# STM32G0B0VET6 register map
File version: 1.0
Registers are 32-bit, access not given, reset 0x0 unless marked. A register's access mark holds for its fields unless they carry their own. Offsets are from the block's base; [hi:lo] are bit positions; {n}, {i} and the like mark numbered series.

## USB_DRD_FS
Base 0x40005C00
{0x0+4i} CHEP{i}R (i=0..7)
0x40 CNTR
0x44 ISTR
0x48 FNR
0x4C DADDR
0x54 LPMCSR
0x58 BCDR

## PWR
Base 0x40007000
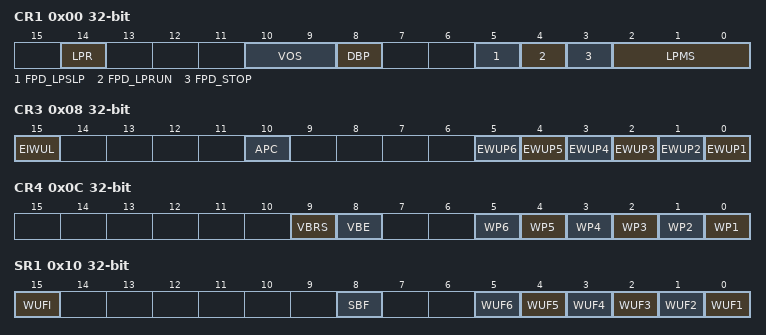
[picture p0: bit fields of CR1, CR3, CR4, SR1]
0x00 CR1
  [14] LPR, [10:9] VOS, [8] DBP, [5] FPD_LPSLP, [4] FPD_LPRUN, [3] FPD_STOP, [2:0] LPMS
0x08 CR3
  [15] EIWUL, [10] APC, [n-1] EWUP{n} (n=1..6)
0x0C CR4
  [9] VBRS, [8] VBE, [n-1] WP{n} (n=1..6)
0x10 SR1
  [15] WUFI, [8] SBF, [n-1] WUF{n} (n=1..6)
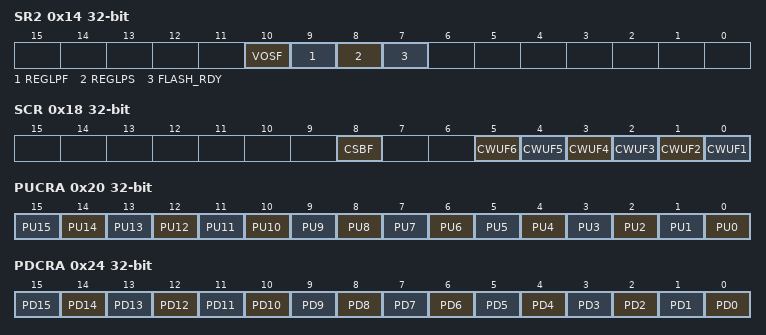
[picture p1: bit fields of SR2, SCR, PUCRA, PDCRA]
0x14 SR2
  [10] VOSF, [9] REGLPF, [8] REGLPS, [7] FLASH_RDY
0x18 SCR
  [8] CSBF, [n-1] CWUF{n} (n=1..6)
0x20 PUCRA
  [n] PU{n} (n=0..15)
0x24 PDCRA
  [n] PD{n} (n=0..15)
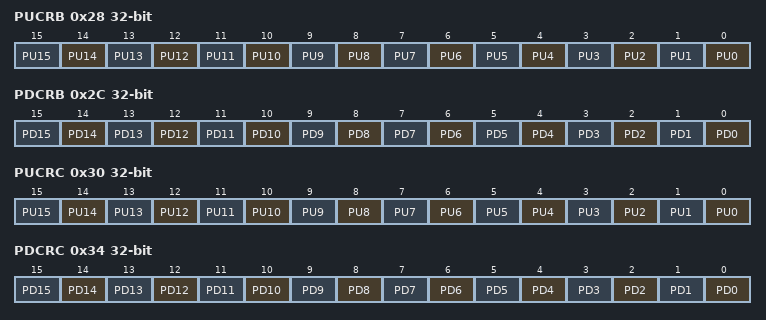
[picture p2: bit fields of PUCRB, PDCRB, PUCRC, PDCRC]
0x28 PUCRB
  [n] PU{n} (n=0..15)
0x2C PDCRB
  [n] PD{n} (n=0..15)
0x30 PUCRC
  [n] PU{n} (n=0..15)
0x34 PDCRC
  [n] PD{n} (n=0..15)
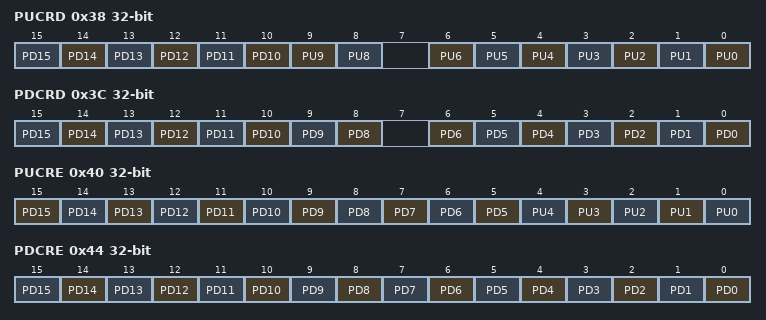
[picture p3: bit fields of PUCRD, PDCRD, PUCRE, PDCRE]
0x38 PUCRD
  [n] PD{n} (n=10..15), [9] PU9, [8] PU8, [n] PU{n} (n=0..6)
0x3C PDCRD
  [n] PD{n} (n=8..15), [n] PD{n} (n=0..6)
0x40 PUCRE
  [n] PD{n} (n=5..15), [n] PU{n} (n=0..4)
0x44 PDCRE
  [n] PD{n} (n=0..15)
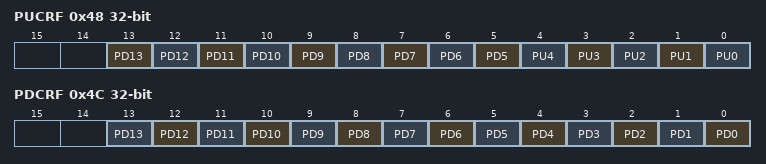
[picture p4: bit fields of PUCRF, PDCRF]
0x48 PUCRF
  [n] PD{n} (n=5..13), [n] PU{n} (n=0..4)
0x4C PDCRF
  [n] PD{n} (n=0..13)

## USB_DRD_PMA_BUFF
Base 0x40009800
0x00 TXBD
0x04 RXBD

## TAMP
Base 0x4000B000
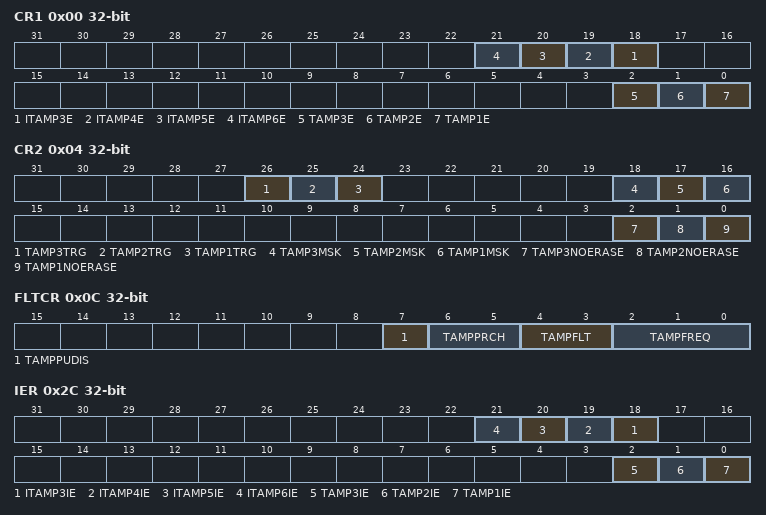
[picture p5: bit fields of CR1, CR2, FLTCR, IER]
0x00 CR1
  [n+15] ITAMP{n}E (n=3..6), [2] TAMP3E, [1] TAMP2E, [0] TAMP1E
0x04 CR2
  [26] TAMP3TRG, [25] TAMP2TRG, [24] TAMP1TRG, [18] TAMP3MSK, [17] TAMP2MSK, [16] TAMP1MSK, [2] TAMP3NOERASE, [1] TAMP2NOERASE, [0] TAMP1NOERASE
0x0C FLTCR
  [7] TAMPPUDIS, [6:5] TAMPPRCH, [4:3] TAMPFLT, [2:0] TAMPFREQ
0x2C IER
  [n+15] ITAMP{n}IE (n=3..6), [2] TAMP3IE, [1] TAMP2IE, [0] TAMP1IE
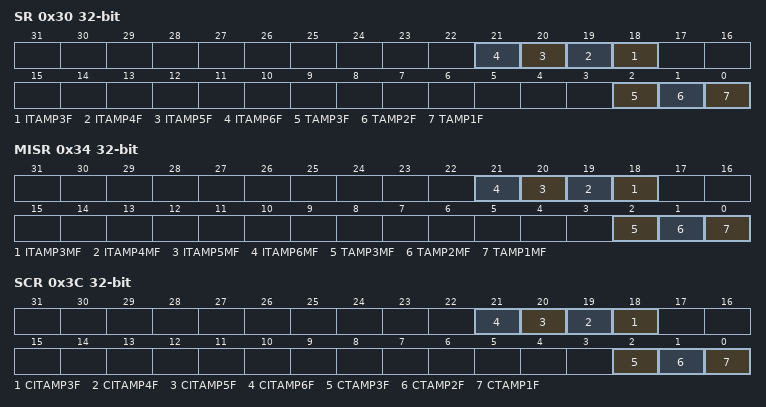
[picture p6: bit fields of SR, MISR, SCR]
0x30 SR
  [n+15] ITAMP{n}F (n=3..6), [2] TAMP3F, [1] TAMP2F, [0] TAMP1F
0x34 MISR
  [n+15] ITAMP{n}MF (n=3..6), [2] TAMP3MF, [1] TAMP2MF, [0] TAMP1MF
0x3C SCR
  [n+15] CITAMP{n}F (n=3..6), [2] CTAMP3F, [1] CTAMP2F, [0] CTAMP1F
{0x100+4i} BKP{i}R (i=0..4)

## SYSCFG
Base 0x40010000
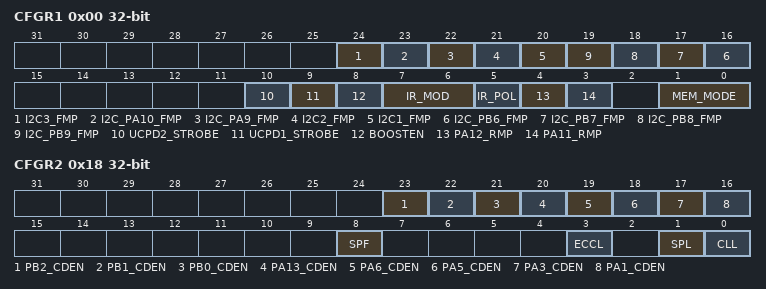
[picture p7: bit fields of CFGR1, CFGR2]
0x00 CFGR1
  [24] I2C3_FMP, [23] I2C_PA10_FMP, [22] I2C_PA9_FMP, [21] I2C2_FMP, [20] I2C1_FMP, [n+10] I2C_PB{n}_FMP (n=6..9), [10] UCPD2_STROBE, [9] UCPD1_STROBE, [8] BOOSTEN, [7:6] IR_MOD, [5] IR_POL, [4] PA12_RMP, [3] PA11_RMP, [1:0] MEM_MODE
0x18 CFGR2
  [23] PB2_CDEN, [22] PB1_CDEN, [21] PB0_CDEN, [20] PA13_CDEN, [19] PA6_CDEN, [18] PA5_CDEN, [17] PA3_CDEN, [16] PA1_CDEN, [8] SPF, [3] ECCL, [1] SPL, [0] CLL
0x80 IT_LINE_SR.0
0x84 IT_LINE_SR.1
0x88 IT_LINE_SR.2
0x8C IT_LINE_SR.3
0x90 IT_LINE_SR.4
0x94 IT_LINE_SR.5
0x98 IT_LINE_SR.6
0x9C IT_LINE_SR.7
0xA0 IT_LINE_SR.8
0xA4 IT_LINE_SR.9
0xA8 IT_LINE_SR.10
0xAC IT_LINE_SR.11
0xB0 IT_LINE_SR.12
0xB4 IT_LINE_SR.13
0xB8 IT_LINE_SR.14
0xBC IT_LINE_SR.15
0xC0 IT_LINE_SR.16
0xC4 IT_LINE_SR.17
0xC8 IT_LINE_SR.18
0xCC IT_LINE_SR.19
0xD0 IT_LINE_SR.20
0xD4 IT_LINE_SR.21
0xD8 IT_LINE_SR.22
0xDC IT_LINE_SR.23
0xE0 IT_LINE_SR.24
0xE4 IT_LINE_SR.25
0xE8 IT_LINE_SR.26
0xEC IT_LINE_SR.27
0xF0 IT_LINE_SR.28
0xF4 IT_LINE_SR.29
0xF8 IT_LINE_SR.30
0xFC IT_LINE_SR.31

## ADC1
Base 0x40012400
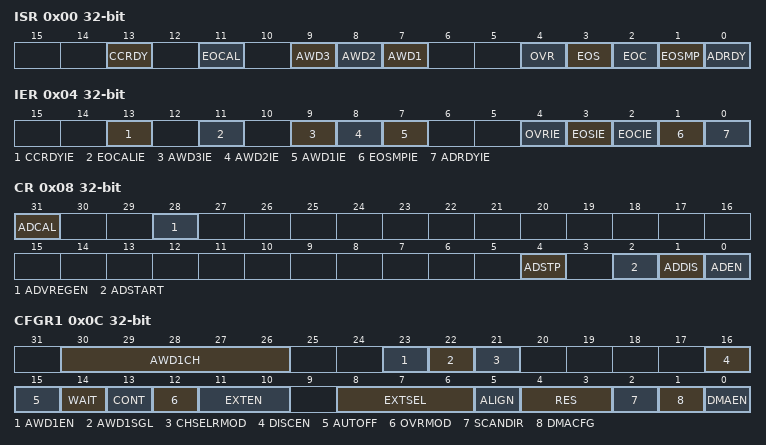
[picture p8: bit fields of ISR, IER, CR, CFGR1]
0x00 ISR
  [13] CCRDY, [11] EOCAL, [9] AWD3, [8] AWD2, [7] AWD1, [4] OVR, [3] EOS, [2] EOC, [1] EOSMP, [0] ADRDY
0x04 IER
  [13] CCRDYIE, [11] EOCALIE, [9] AWD3IE, [8] AWD2IE, [7] AWD1IE, [4] OVRIE, [3] EOSIE, [2] EOCIE, [1] EOSMPIE, [0] ADRDYIE
0x08 CR
  [31] ADCAL, [28] ADVREGEN, [4] ADSTP, [2] ADSTART, [1] ADDIS, [0] ADEN
0x0C CFGR1
  [30:26] AWD1CH, [23] AWD1EN, [22] AWD1SGL, [21] CHSELRMOD, [16] DISCEN, [15] AUTOFF, [14] WAIT, [13] CONT, [12] OVRMOD, [11:10] EXTEN, [8:6] EXTSEL, [5] ALIGN, [4:3] RES, [2] SCANDIR, [1] DMACFG, [0] DMAEN
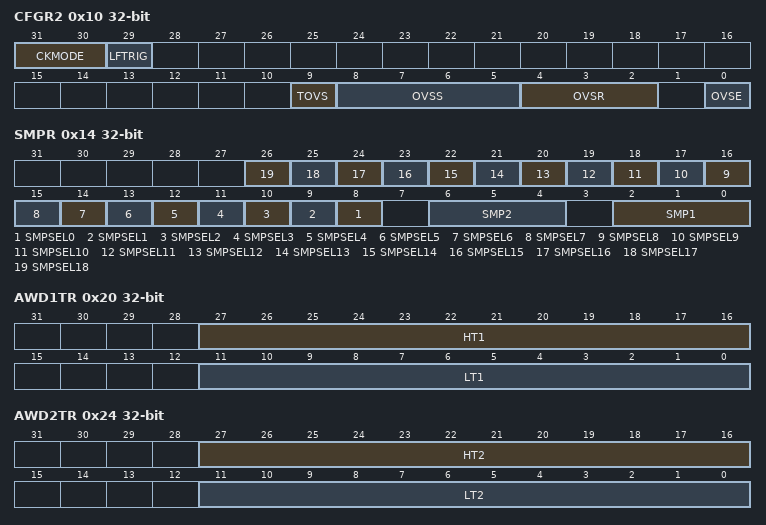
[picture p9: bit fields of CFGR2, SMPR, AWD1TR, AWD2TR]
0x10 CFGR2
  [31:30] CKMODE, [29] LFTRIG, [9] TOVS, [8:5] OVSS, [4:2] OVSR, [0] OVSE
0x14 SMPR
  [n+8] SMPSEL{n} (n=0..18), [6:4] SMP2, [2:0] SMP1
0x20 AWD1TR
  [27:16] HT1, [11:0] LT1
0x24 AWD2TR
  [27:16] HT2, [11:0] LT2
0x28 CHSELR
  [4n-1:4n-4] SQ{n} (n=2..8), [18] CHSEL18, [17] CHSEL17, [15] CHSEL15, [14] CHSEL14, [13] CHSEL13, [11] CHSEL11, [10] CHSEL10, [9] CHSEL9, [7] CHSEL7, [6] CHSEL6, [5] CHSEL5, [3] CHSEL3, [2] CHSEL2, [1] CHSEL1, [31:0] SQ_ALL
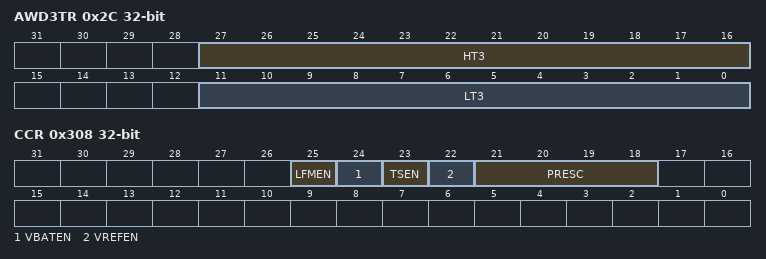
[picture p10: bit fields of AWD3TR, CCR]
0x2C AWD3TR
  [27:16] HT3, [11:0] LT3
0x40 DR
  [15:0] DATA
0xA0 AWD2CR
  [18:0] AWD2CH
0xA4 AWD3CR
  [18:0] AWD3CH
0xB4 CALFACT
  [6:0] CALFACT
0x308 CCR
  [25] LFMEN, [24] VBATEN, [23] TSEN, [22] VREFEN, [21:18] PRESC
